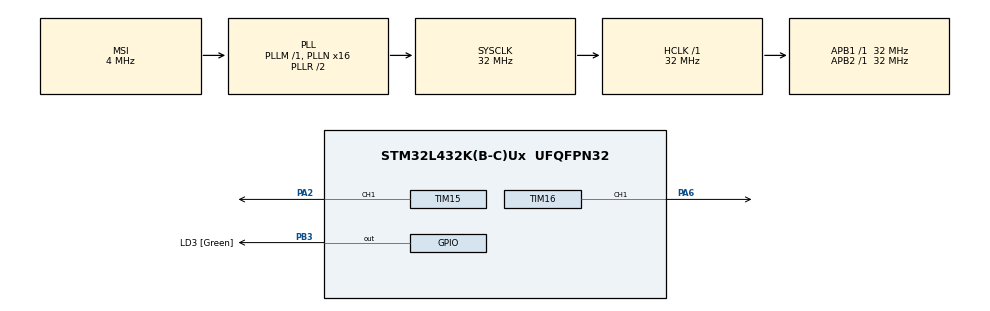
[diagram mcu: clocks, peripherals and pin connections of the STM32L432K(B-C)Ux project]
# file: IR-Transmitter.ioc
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Mcu.Family=STM32L4
Mcu.Name=STM32L432K(B-C)Ux
Mcu.Package=UFQFPN32
NVIC.PriorityGroup=NVIC_PRIORITYGROUP_4
NVIC.TIM1_BRK_TIM15_IRQn=true\:0\:0\:false\:false\:true\:true\:true\:true
NVIC.TIM1_UP_TIM16_IRQn=true\:0\:0\:false\:false\:true\:true\:true\:true
PA0.GPIO_Label=MCO [High speed clock in]
PA0.Mode=HSE-External-Clock-Source-for-LittleOrca
PA0.Signal=RCC_CK_IN
PA13\ (JTMS-SWDIO).Signal=SYS_JTMS-SWDIO
PA14\ (JTCK-SWCLK).GPIO_Label=SWCLK
PA14\ (JTCK-SWCLK).Signal=SYS_JTCK-SWCLK
PA15\ (JTDI).GPIO_Label=VCP_RX
PA15\ (JTDI).Signal=USART2_RX
PA2.Signal=S_TIM15_CH1
PA6.Signal=S_TIM16_CH1
PB3\ (JTDO-TRACESWO).GPIO_Label=LD3 [Green]
PB3\ (JTDO-TRACESWO).Signal=GPIO_Output
PC14-OSC32_IN\ (PC14).Mode=LSE-External-Oscillator
PC14-OSC32_IN\ (PC14).Signal=RCC_OSC32_IN
PC15-OSC32_OUT\ (PC15).Mode=LSE-External-Oscillator
PC15-OSC32_OUT\ (PC15).Signal=RCC_OSC32_OUT
ProjectManager.HeapSize=0x200
ProjectManager.StackSize=0x400
ProjectManager.TargetToolchain=MDK-ARM V5.32
RCC.AHBFreq_Value=32000000
RCC.APB1Freq_Value=32000000
RCC.APB1TimFreq_Value=32000000
RCC.APB2Freq_Value=32000000
RCC.APB2TimFreq_Value=32000000
RCC.CortexFreq_Value=32000000
RCC.HCLKFreq_Value=32000000
RCC.HSE_VALUE=8000000
RCC.HSI16_VALUE=16000000
RCC.HSI48_VALUE=48000000
RCC.HSI_VALUE=16000000
RCC.MSI_VALUE=4000000
RCC.PLLMUL=RCC_PLLMUL_4
RCC.PLLN=16
RCC.SYSCLKFreq_VALUE=32000000
RCC.SYSCLKSource=RCC_SYSCLKSOURCE_PLLCLK
RCC.VCOOutputFreq_Value=64000000
SH.S_TIM15_CH1.0=TIM15_CH1,PWM Generation1 CH1
SH.S_TIM16_CH1.0=TIM16_CH1,PWM Generation1 CH1
TIM15.AutoReloadPreload=TIM_AUTORELOAD_PRELOAD_ENABLE
TIM15.Channel-PWM\ Generation1\ CH1=TIM_CHANNEL_1
TIM15.Period=888
TIM15.Prescaler=31
TIM16.AutoReloadPreload=TIM_AUTORELOAD_PRELOAD_ENABLE
TIM16.Channel=TIM_CHANNEL_1
TIM16.Period=842
TIM16.Prescaler=0
TIM16.Pulse=210
VP_TIM15_VS_ClockSourceINT.Mode=Internal
VP_TIM16_VS_ClockSourceINT.Mode=Enable_Timer
board=NUCLEO-L432KC

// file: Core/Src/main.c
/* USER CODE BEGIN Header */
/**
  ******************************************************************************
  * @file           : main.c
  * @brief          : Main program body
  ******************************************************************************
  * @attention
  *
  * Copyright (c) 2026 STMicroelectronics.
  * All rights reserved.
  *
  * This software is licensed under terms that can be found in the LICENSE file
  * in the root directory of this software component.
  * If no LICENSE file comes with this software, it is provided AS-IS.
  *
  ******************************************************************************
  */
/* USER CODE END Header */
#include "main.h"

/* USER CODE BEGIN Includes */
#include <stdint.h>
/* USER CODE END Includes */

/* USER CODE BEGIN PD */
/* RC5 defines moved to main.h */
#define BUTTON_PIN GPIO_PIN_4
#define BUTTON_PORT GPIOA
/* USER CODE END PD */

/* USER CODE BEGIN PM */
/* RC5 Control bit enum */
typedef enum
{
  RC5_CTRL_RESET = ((uint16_t)0),
  RC5_CTRL_SET   = ((uint16_t)0x0800)
} RC5_Ctrl_t;
/* USER CODE END PM */

TIM_HandleTypeDef htim15;
TIM_HandleTypeDef htim16;

/* USER CODE BEGIN PV */
/* RC5 Encoder Timer Handles */
TIM_HandleTypeDef TimHandleHF;  /* High frequency (envelope) - TIM15 */
TIM_HandleTypeDef TimHandleLF;  /* Low frequency (carrier) - TIM16 */

/* RC5 Frame data */
uint16_t RC5BinaryFrameFormat = 0;
uint32_t RC5ManchesterFrameFormat = 0;
uint8_t RC5SendOpCompleteFlag = 0x01;  /* Start as complete so first send can proceed */
uint8_t RC5SendOpReadyFlag = 0;
uint32_t BitsSentCounter = 0;

/* RC5 Toggle Bit State */
static RC5_Ctrl_t RC5_Toggle_Bit = RC5_CTRL_RESET;
static uint8_t Button_Previous_State = 1; // Active Low: 1 = released, 0 = pressed
/* USER CODE END PV */

void SystemClock_Config(void);
static void MX_GPIO_Init(void);
static void MX_TIM15_Init(void);
static void MX_TIM16_Init(void);
/* USER CODE BEGIN PFP */
void RC5_Send(uint8_t address, uint8_t command);
void RC5_TimerIRQHandler(void);
void RC5_Encode_Init(void);
void RC5_Encode_SendFrame(uint8_t RC5_Address, uint8_t RC5_Instruction, RC5_Ctrl_t RC5_Ctrl);
void RC5_Encode_SignalGenerate(void);
static uint16_t RC5_BinFrameGeneration(uint8_t RC5_Address, uint8_t RC5_Instruction, RC5_Ctrl_t RC5_Ctrl);
static uint32_t RC5_ManchesterConvert(uint16_t RC5_BinaryFrameFormat);
/* USER CODE END PFP */

int main(void)
{

  /* MCU Configuration--------------------------------------------------------*/

  /* Reset of all peripherals, Initializes the Flash interface and the Systick. */
  HAL_Init();

  /* Configure the system clock */
  SystemClock_Config();

  /* Initialize all configured peripherals */
  MX_GPIO_Init();
  MX_TIM15_Init();
  MX_TIM16_Init();
  /* USER CODE BEGIN 2 */
  RC5_Encode_Init();  /* Initialize RC5 timers once at startup */

  /* USER CODE END 2 */

  /* Infinite loop */
  while (1)
  {

    /* USER CODE BEGIN 3 */
    /* Check Button State (Active LOW) */
    if (HAL_GPIO_ReadPin(BUTTON_PORT, BUTTON_PIN) == GPIO_PIN_RESET)
    {
       /* Button is Pressed */
       if (Button_Previous_State == 1) /* Was released, now pressed -> Toggle */
       {
           if (RC5_Toggle_Bit == RC5_CTRL_RESET)
           {
               RC5_Toggle_Bit = RC5_CTRL_SET;
           }
           else
           {
               RC5_Toggle_Bit = RC5_CTRL_RESET;
           }
           Button_Previous_State = 0; /* Mark as pressed */
       }

       /* Send RC5 Frame with current Toggle Bit */
       RC5_Encode_SendFrame(0x10, 0x20, RC5_Toggle_Bit);

       HAL_GPIO_WritePin(LD3_GPIO_Port, LD3_Pin, GPIO_PIN_SET);
       HAL_Delay(200); /* Delay for repeat interval and debounce */
    }
    else
    {
       /* Button is Released */
       HAL_GPIO_WritePin(LD3_GPIO_Port, LD3_Pin, GPIO_PIN_RESET);
       Button_Previous_State = 1; /* Mark as released */
    }
  }
  /* USER CODE END 3 */
}

void SystemClock_Config(void)
{
  RCC_OscInitTypeDef RCC_OscInitStruct = {0};
  RCC_ClkInitTypeDef RCC_ClkInitStruct = {0};

  /** Configure the main internal regulator output voltage
  */
  if (HAL_PWREx_ControlVoltageScaling(PWR_REGULATOR_VOLTAGE_SCALE1) != HAL_OK)
  {
    Error_Handler();
  }

  /** Configure LSE Drive Capability
  */
  HAL_PWR_EnableBkUpAccess();
  __HAL_RCC_LSEDRIVE_CONFIG(RCC_LSEDRIVE_LOW);

  /** Initializes the RCC Oscillators according to the specified parameters
  * in the RCC_OscInitTypeDef structure.
  */
  RCC_OscInitStruct.OscillatorType = RCC_OSCILLATORTYPE_LSE|RCC_OSCILLATORTYPE_MSI;
  RCC_OscInitStruct.LSEState = RCC_LSE_ON;
  RCC_OscInitStruct.MSIState = RCC_MSI_ON;
  RCC_OscInitStruct.MSICalibrationValue = 0;
  RCC_OscInitStruct.MSIClockRange = RCC_MSIRANGE_6;
  RCC_OscInitStruct.PLL.PLLState = RCC_PLL_ON;
  RCC_OscInitStruct.PLL.PLLSource = RCC_PLLSOURCE_MSI;
  RCC_OscInitStruct.PLL.PLLM = 1;
  RCC_OscInitStruct.PLL.PLLN = 16;
  RCC_OscInitStruct.PLL.PLLP = RCC_PLLP_DIV7;
  RCC_OscInitStruct.PLL.PLLQ = RCC_PLLQ_DIV2;
  RCC_OscInitStruct.PLL.PLLR = RCC_PLLR_DIV2;
  if (HAL_RCC_OscConfig(&RCC_OscInitStruct) != HAL_OK)
  {
    Error_Handler();
  }

  /** Initializes the CPU, AHB and APB buses clocks
  */
  RCC_ClkInitStruct.ClockType = RCC_CLOCKTYPE_HCLK|RCC_CLOCKTYPE_SYSCLK
                              |RCC_CLOCKTYPE_PCLK1|RCC_CLOCKTYPE_PCLK2;
  RCC_ClkInitStruct.SYSCLKSource = RCC_SYSCLKSOURCE_PLLCLK;
  RCC_ClkInitStruct.AHBCLKDivider = RCC_SYSCLK_DIV1;
  RCC_ClkInitStruct.APB1CLKDivider = RCC_HCLK_DIV1;
  RCC_ClkInitStruct.APB2CLKDivider = RCC_HCLK_DIV1;

  if (HAL_RCC_ClockConfig(&RCC_ClkInitStruct, FLASH_LATENCY_1) != HAL_OK)
  {
    Error_Handler();
  }

  /** Enable MSI Auto calibration
  */
  HAL_RCCEx_EnableMSIPLLMode();
}

static void MX_TIM15_Init(void)
{

  TIM_ClockConfigTypeDef sClockSourceConfig = {0};
  TIM_MasterConfigTypeDef sMasterConfig = {0};
  TIM_OC_InitTypeDef sConfigOC = {0};
  TIM_BreakDeadTimeConfigTypeDef sBreakDeadTimeConfig = {0};

  htim15.Instance = TIM15;
  htim15.Init.Prescaler = 31;
  htim15.Init.CounterMode = TIM_COUNTERMODE_UP;
  htim15.Init.Period = 888;
  htim15.Init.ClockDivision = TIM_CLOCKDIVISION_DIV1;
  htim15.Init.RepetitionCounter = 0;
  htim15.Init.AutoReloadPreload = TIM_AUTORELOAD_PRELOAD_ENABLE;
  if (HAL_TIM_Base_Init(&htim15) != HAL_OK)
  {
    Error_Handler();
  }
  sClockSourceConfig.ClockSource = TIM_CLOCKSOURCE_INTERNAL;
  if (HAL_TIM_ConfigClockSource(&htim15, &sClockSourceConfig) != HAL_OK)
  {
    Error_Handler();
  }
  if (HAL_TIM_PWM_Init(&htim15) != HAL_OK)
  {
    Error_Handler();
  }
  sMasterConfig.MasterOutputTrigger = TIM_TRGO_RESET;
  sMasterConfig.MasterSlaveMode = TIM_MASTERSLAVEMODE_DISABLE;
  if (HAL_TIMEx_MasterConfigSynchronization(&htim15, &sMasterConfig) != HAL_OK)
  {
    Error_Handler();
  }
  sConfigOC.OCMode = TIM_OCMODE_PWM1;
  sConfigOC.Pulse = 0;
  sConfigOC.OCPolarity = TIM_OCPOLARITY_HIGH;
  sConfigOC.OCNPolarity = TIM_OCNPOLARITY_HIGH;
  sConfigOC.OCFastMode = TIM_OCFAST_DISABLE;
  sConfigOC.OCIdleState = TIM_OCIDLESTATE_RESET;
  sConfigOC.OCNIdleState = TIM_OCNIDLESTATE_RESET;
  if (HAL_TIM_PWM_ConfigChannel(&htim15, &sConfigOC, TIM_CHANNEL_1) != HAL_OK)
  {
    Error_Handler();
  }
  sBreakDeadTimeConfig.OffStateRunMode = TIM_OSSR_DISABLE;
  sBreakDeadTimeConfig.OffStateIDLEMode = TIM_OSSI_DISABLE;
  sBreakDeadTimeConfig.LockLevel = TIM_LOCKLEVEL_OFF;
  sBreakDeadTimeConfig.DeadTime = 0;
  sBreakDeadTimeConfig.BreakState = TIM_BREAK_DISABLE;
  sBreakDeadTimeConfig.BreakPolarity = TIM_BREAKPOLARITY_HIGH;
  sBreakDeadTimeConfig.AutomaticOutput = TIM_AUTOMATICOUTPUT_DISABLE;
  if (HAL_TIMEx_ConfigBreakDeadTime(&htim15, &sBreakDeadTimeConfig) != HAL_OK)
  {
    Error_Handler();
  }
  HAL_TIM_MspPostInit(&htim15);

}

static void MX_TIM16_Init(void)
{

  TIM_OC_InitTypeDef sConfigOC = {0};
  TIM_BreakDeadTimeConfigTypeDef sBreakDeadTimeConfig = {0};

  htim16.Instance = TIM16;
  htim16.Init.Prescaler = 0;
  htim16.Init.CounterMode = TIM_COUNTERMODE_UP;
  htim16.Init.Period = 841;  /* 32MHz / 842 = 37,980 Hz ≈ 38kHz */
  htim16.Init.ClockDivision = TIM_CLOCKDIVISION_DIV1;
  htim16.Init.RepetitionCounter = 0;
  htim16.Init.AutoReloadPreload = TIM_AUTORELOAD_PRELOAD_ENABLE;
  if (HAL_TIM_Base_Init(&htim16) != HAL_OK)
  {
    Error_Handler();
  }
  if (HAL_TIM_PWM_Init(&htim16) != HAL_OK)
  {
    Error_Handler();
  }
  sConfigOC.OCMode = TIM_OCMODE_PWM1;
  sConfigOC.Pulse = 210;
  sConfigOC.OCPolarity = TIM_OCPOLARITY_HIGH;
  sConfigOC.OCNPolarity = TIM_OCNPOLARITY_HIGH;
  sConfigOC.OCFastMode = TIM_OCFAST_DISABLE;
  sConfigOC.OCIdleState = TIM_OCIDLESTATE_RESET;
  sConfigOC.OCNIdleState = TIM_OCNIDLESTATE_RESET;
  if (HAL_TIM_PWM_ConfigChannel(&htim16, &sConfigOC, TIM_CHANNEL_1) != HAL_OK)
  {
    Error_Handler();
  }
  sBreakDeadTimeConfig.OffStateRunMode = TIM_OSSR_DISABLE;
  sBreakDeadTimeConfig.OffStateIDLEMode = TIM_OSSI_DISABLE;
  sBreakDeadTimeConfig.LockLevel = TIM_LOCKLEVEL_OFF;
  sBreakDeadTimeConfig.DeadTime = 0;
  sBreakDeadTimeConfig.BreakState = TIM_BREAK_DISABLE;
  sBreakDeadTimeConfig.BreakPolarity = TIM_BREAKPOLARITY_HIGH;
  sBreakDeadTimeConfig.AutomaticOutput = TIM_AUTOMATICOUTPUT_DISABLE;
  if (HAL_TIMEx_ConfigBreakDeadTime(&htim16, &sBreakDeadTimeConfig) != HAL_OK)
  {
    Error_Handler();
  }
  HAL_TIM_MspPostInit(&htim16);

}

static void MX_GPIO_Init(void)
{
  GPIO_InitTypeDef GPIO_InitStruct = {0};

  /* GPIO Ports Clock Enable */
  __HAL_RCC_GPIOC_CLK_ENABLE();
  __HAL_RCC_GPIOA_CLK_ENABLE();
  __HAL_RCC_GPIOB_CLK_ENABLE();

  /*Configure GPIO pin Output Level */
  HAL_GPIO_WritePin(LD3_GPIO_Port, LD3_Pin, GPIO_PIN_RESET);

  /*Configure GPIO pin : VCP_RX_Pin */
  GPIO_InitStruct.Pin = VCP_RX_Pin;
  GPIO_InitStruct.Mode = GPIO_MODE_AF_PP;
  GPIO_InitStruct.Pull = GPIO_NOPULL;
  GPIO_InitStruct.Speed = GPIO_SPEED_FREQ_VERY_HIGH;
  GPIO_InitStruct.Alternate = GPIO_AF3_USART2;
  HAL_GPIO_Init(VCP_RX_GPIO_Port, &GPIO_InitStruct);

  /*Configure GPIO pin : LD3_Pin */
  GPIO_InitStruct.Pin = LD3_Pin;
  GPIO_InitStruct.Mode = GPIO_MODE_OUTPUT_PP;
  GPIO_InitStruct.Pull = GPIO_NOPULL;
  GPIO_InitStruct.Speed = GPIO_SPEED_FREQ_LOW;
  HAL_GPIO_Init(LD3_GPIO_Port, &GPIO_InitStruct);

  /* USER CODE BEGIN MX_GPIO_Init_2 */
  /* Configure GPIO pin : BUTTON_PIN */
  GPIO_InitStruct.Pin = BUTTON_PIN;
  GPIO_InitStruct.Mode = GPIO_MODE_INPUT;
  GPIO_InitStruct.Pull = GPIO_PULLUP;
  HAL_GPIO_Init(BUTTON_PORT, &GPIO_InitStruct);
  /* USER CODE END MX_GPIO_Init_2 */
}

/* USER CODE BEGIN 4 */
void HAL_TIM_PeriodElapsedCallback(TIM_HandleTypeDef *htim)
{
    if (htim->Instance == TIM15)  /* TIM15 fires every 889us -> Manchester bit timing */
    {
        RC5_TimerIRQHandler();
    }
}

/* RC5 Encoder wrapper functions */
void RC5_Send(uint8_t address, uint8_t command)
{
    RC5_Encode_SendFrame(address, command, RC5_CTRL_RESET);
}

void RC5_TimerIRQHandler(void)
{
    RC5_Encode_SignalGenerate();
}

/* RC5 Encoder implementation functions */
void RC5_Encode_Init(void)
{
  TIM_OC_InitTypeDef ch_config;
  GPIO_InitTypeDef gpio_init_struct;

  /* TIM15 & TIM16 clock enable */
  __HAL_RCC_TIM15_CLK_ENABLE();
  __HAL_RCC_TIM16_CLK_ENABLE();

  TimHandleHF.Instance = TIM15;  /* Envelope timer */
  TimHandleLF.Instance = TIM16;  /* Carrier timer */

  /* ===== TIM15 ENVELOPE OUTPUT ON PA2 ===== */
  gpio_init_struct.Pin = GPIO_PIN_2;
  gpio_init_struct.Mode = GPIO_MODE_AF_PP;
  gpio_init_struct.Pull = GPIO_NOPULL;
  gpio_init_struct.Speed = GPIO_SPEED_FREQ_HIGH;
  gpio_init_struct.Alternate = GPIO_AF14_TIM15;
  HAL_GPIO_Init(GPIOA, &gpio_init_struct);

  TimHandleHF.Init.Prescaler = TIM15_PRESCALER;
  TimHandleHF.Init.CounterMode = TIM_COUNTERMODE_UP;
  TimHandleHF.Init.Period = TIM15_PERIOD;
  TimHandleHF.Init.ClockDivision = TIM_CLOCKDIVISION_DIV1;
  TimHandleHF.Init.RepetitionCounter = 0;
  HAL_TIM_Base_Init(&TimHandleHF);

  ch_config.OCMode = TIM_OCMODE_PWM1;
  ch_config.Pulse = TIM15_PERIOD / 2;
  ch_config.OCPolarity = TIM_OCPOLARITY_HIGH;
  ch_config.OCNPolarity = TIM_OCNPOLARITY_HIGH;
  ch_config.OCFastMode = TIM_OCFAST_DISABLE;
  HAL_TIM_PWM_ConfigChannel(&TimHandleHF, &ch_config, TIM_CHANNEL_1);
  HAL_TIM_PWM_Start(&TimHandleHF, TIM_CHANNEL_1);

  /* ===== TIM16 CARRIER 38kHz ON PA6 ===== */
  gpio_init_struct.Pin = GPIO_PIN_6;
  gpio_init_struct.Mode = GPIO_MODE_AF_PP;
  gpio_init_struct.Pull = GPIO_NOPULL;
  gpio_init_struct.Speed = GPIO_SPEED_FREQ_HIGH;
  gpio_init_struct.Alternate = GPIO_AF14_TIM16;
  HAL_GPIO_Init(GPIOA, &gpio_init_struct);

  TimHandleLF.Init.Prescaler = TIM16_PRESCALER;
  TimHandleLF.Init.CounterMode = TIM_COUNTERMODE_UP;
  TimHandleLF.Init.Period = TIM16_PERIOD;
  TimHandleLF.Init.ClockDivision = TIM_CLOCKDIVISION_DIV1;
  TimHandleLF.Init.RepetitionCounter = 0;
  HAL_TIM_Base_Init(&TimHandleLF);

  ch_config.OCMode = TIM_OCMODE_PWM1;
  ch_config.Pulse = 0;  /* Carrier OFF initially */
  ch_config.OCPolarity = TIM_OCPOLARITY_HIGH;
  ch_config.OCNPolarity = TIM_OCNPOLARITY_HIGH;
  ch_config.OCFastMode = TIM_OCFAST_DISABLE;
  HAL_TIM_PWM_ConfigChannel(&TimHandleLF, &ch_config, TIM_CHANNEL_1);
  HAL_TIM_PWM_Start(&TimHandleLF, TIM_CHANNEL_1);
  __HAL_TIM_MOE_ENABLE(&TimHandleLF);
  /* TIM15 IT is started only when a frame is ready to send */
}

void RC5_Encode_SendFrame(uint8_t RC5_Address, uint8_t RC5_Instruction, RC5_Ctrl_t RC5_Ctrl)
{
  /* Generate a binary format of the Frame */
  RC5BinaryFrameFormat = RC5_BinFrameGeneration(RC5_Address, RC5_Instruction, RC5_Ctrl);

  /* Generate a Manchester format of the Frame */
  RC5ManchesterFrameFormat = RC5_ManchesterConvert(RC5BinaryFrameFormat);

  /* Set the Send operation Ready flag to indicate that the frame is ready to be sent */
  RC5SendOpReadyFlag = 1;
  BitsSentCounter = 0;

  /* Start TIM15 interrupt to drive Manchester bit timing (889us per half-bit) */
  HAL_TIM_Base_Start_IT(&TimHandleHF);
}

void RC5_Encode_SignalGenerate(void)
{
  uint32_t bit_msg = 0;

  if ((RC5SendOpReadyFlag == 1) && (BitsSentCounter <= (RC5GlobalFrameLength * 2)))
  {
    RC5SendOpCompleteFlag = 0x00;
    bit_msg = (uint8_t)((RC5ManchesterFrameFormat >> BitsSentCounter) & 1);

    if (bit_msg == 1)
    {
      /* Carrier ON: 38kHz burst visible on PA6 */
      __HAL_TIM_SET_COMPARE(&TimHandleLF, TIM_CHANNEL_1, TIM16_PULSE);
    }
    else
    {
      /* Carrier OFF: silence on PA6 */
      __HAL_TIM_SET_COMPARE(&TimHandleLF, TIM_CHANNEL_1, 0);
    }
    BitsSentCounter++;
  }
  else
  {
    RC5SendOpCompleteFlag = 0x01;

    /* Stop TIM15 interrupt - frame transmission complete */
    HAL_TIM_Base_Stop_IT(&TimHandleHF);
    RC5SendOpReadyFlag = 0;
    BitsSentCounter = 0;
    /* Carrier OFF at end of frame */
    __HAL_TIM_SET_COMPARE(&TimHandleLF, TIM_CHANNEL_1, 0);
  }
}

static uint16_t RC5_BinFrameGeneration(uint8_t RC5_Address, uint8_t RC5_Instruction, RC5_Ctrl_t RC5_Ctrl)
{
  uint16_t star1 = 0x2000;
  uint16_t star2 = 0x1000;
  uint16_t addr = 0;

  while (RC5SendOpCompleteFlag == 0x00)
  {}

  /* Check if Instruction is 128-bit length */
  if (RC5_Instruction >= 64)
  {
    /* Reset field bit: command is 7-bit length */
    star2 = 0;
    /* Keep the lowest 6 bits of the command */
    RC5_Instruction &= 0x003F;
  }
  else /* Instruction is 64-bit length */
  {
    /* Set field bit: command is 6-bit length */
    star2 = 0x1000;
  }

  RC5SendOpReadyFlag = 0;
  RC5ManchesterFrameFormat = 0;
  RC5BinaryFrameFormat = 0;
  addr = ((uint16_t)(RC5_Address)) << 6;
  RC5BinaryFrameFormat = (star1) | (star2) | (RC5_Ctrl) | (addr) | (RC5_Instruction);
  return (RC5BinaryFrameFormat);
}

static uint32_t RC5_ManchesterConvert(uint16_t RC5_BinaryFrameFormat)
{
  uint8_t i = 0;
  uint16_t Mask = 1;
  uint16_t bit_format = 0;
  uint32_t ConvertedMsg = 0;

  for (i = 0; i < RC5RealFrameLength; i++)
  {
    bit_format = ((((uint16_t)(RC5_BinaryFrameFormat)) >> i) & Mask) << i;
    ConvertedMsg = ConvertedMsg << 2;

    if (bit_format != 0) /* Manchester 1 -|_ */
    {
      ConvertedMsg |= RC5HIGHSTATE;
    }
    else /* Manchester 0 _|- */
    {
      ConvertedMsg |= RC5LOWSTATE;
    }
  }
  return (ConvertedMsg);
}
/* USER CODE END 4 */

void Error_Handler(void)
{
  __disable_irq();
  while (1)
  {
  }
}
